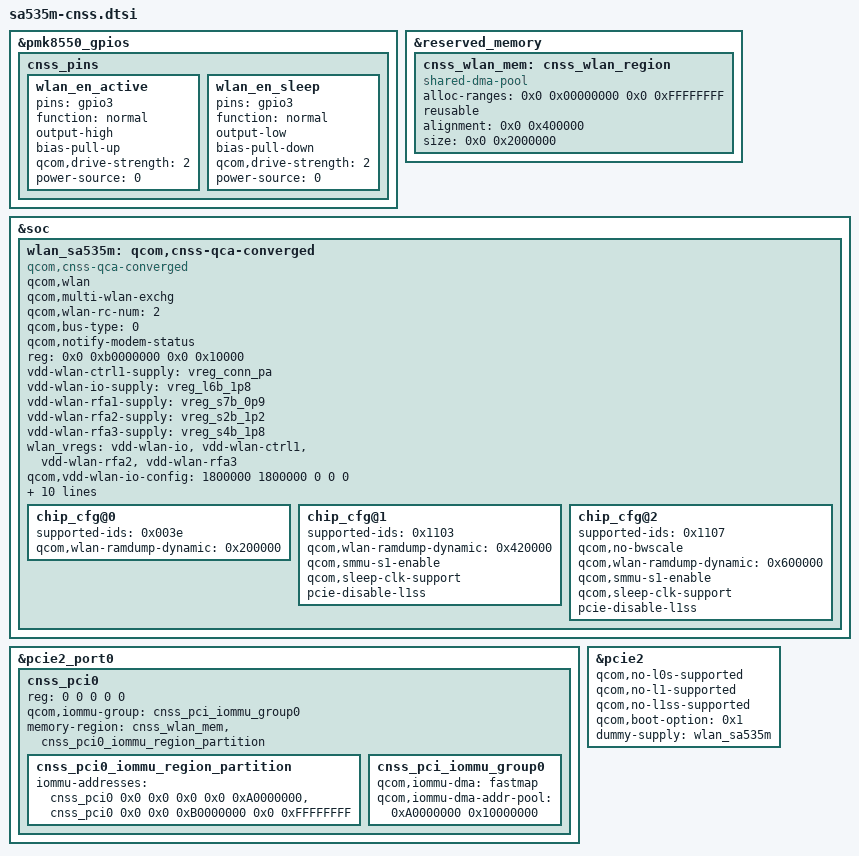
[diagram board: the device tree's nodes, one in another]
// SPDX-License-Identifier: BSD-3-Clause
/*
 * Copyright (c) Qualcomm Technologies, Inc. and/or its subsidiaries.
 */

#include <dt-bindings/interconnect/qcom,echo.h>
#include <dt-bindings/clock/qcom,rpmh.h>
#include <dt-bindings/iio/qcom,spmi-adc5-gen3-pmk8550.h>
#include <dt-bindings/pinctrl/qcom,pmic-gpio.h>
&pmk8550_gpios {
	cnss_pins {
		wlan_en_active: wlan_en_active {
			pins = "gpio3";
			function = "normal";
			output-high;
			bias-pull-up;
			qcom,drive-strength = <2>;
			power-source = <0>;
		};

		wlan_en_sleep: wlan_en_sleep {
			pins = "gpio3";
			function = "normal";
			output-low;
			bias-pull-down;
			qcom,drive-strength = <2>;
			power-source = <0>;
		};
	};
};

&reserved_memory {
	cnss_wlan_mem: cnss_wlan_region {
		compatible = "shared-dma-pool";
		alloc-ranges = <0x0 0x00000000 0x0 0xFFFFFFFF>;
		reusable;
		alignment = <0x0 0x400000>;
		size = <0x0 0x2000000>;
	};
};

&soc {
	wlan_sa535m: qcom,cnss-qca-converged {
		compatible = "qcom,cnss-qca-converged";
		qcom,wlan;
		qcom,multi-wlan-exchg;
		qcom,wlan-rc-num = <2>;
		qcom,bus-type=<0>;
		qcom,notify-modem-status;
		reg = <0x0 0xb0000000 0x0 0x10000>;
		reg-names = "smmu_iova_ipa";

		vdd-wlan-ctrl1-supply = <&vreg_conn_pa>;
		vdd-wlan-io-supply = <&vreg_l6b_1p8>;
		vdd-wlan-rfa1-supply = <&vreg_s7b_0p9>;
		vdd-wlan-rfa2-supply = <&vreg_s2b_1p2>;
		vdd-wlan-rfa3-supply = <&vreg_s4b_1p8>;
		wlan_vregs = "vdd-wlan-io", "vdd-wlan-ctrl1",
				"vdd-wlan-rfa2", "vdd-wlan-rfa3";
		qcom,vdd-wlan-io-config = <1800000 1800000 0 0 0>;
		qcom,vdd-wlan-ctrl1-config = <0 0 0 0 0>;
		qcom,vdd-wlan-rfa1-config = <1000000 1000000 0 0 0>;
		qcom,vdd-wlan-rfa2-config = <1300000 1300000 0 0 0>;
		qcom,vdd-wlan-rfa3-config = <1904000 1904000 450000 0 0>;
		wlan-en-gpio = <&pmk8550_gpios 3 0>;
		pinctrl-names = "wlan_en_active", "wlan_en_sleep";
		pinctrl-0 = <&wlan_en_active>;
		pinctrl-1 = <&wlan_en_sleep>;

		chip_cfg@0 {
			supported-ids = <0x003e>;
			qcom,wlan-ramdump-dynamic = <0x200000>;
		};

		chip_cfg@1 {
			supported-ids = <0x1103>;
			qcom,wlan-ramdump-dynamic = <0x420000>;
			qcom,smmu-s1-enable;
			qcom,sleep-clk-support;
			pcie-disable-l1ss;
		};

		chip_cfg@2 {
			supported-ids = <0x1107>;
			qcom,no-bwscale;
			qcom,wlan-ramdump-dynamic = <0x600000>;
			qcom,smmu-s1-enable;
			qcom,sleep-clk-support;
			pcie-disable-l1ss;
		};
	};
};

&pcie2_port0 {
	cnss_pci0: cnss_pci0 {
		reg = <0 0 0 0 0>;
		qcom,iommu-group = <&cnss_pci_iommu_group0>;
		memory-region = <&cnss_wlan_mem &cnss_pci0_iommu_region_partition>;

		cnss_pci0_iommu_region_partition: cnss_pci0_iommu_region_partition {
			iommu-addresses = <&cnss_pci0 0x0 0x0 0x0 0x0 0xA0000000>,
					  <&cnss_pci0 0x0 0x0 0xB0000000 0x0 0xFFFFFFFF>;
		};

		/* Used by cnss2 only for compatibility */
		cnss_pci_iommu_group0: cnss_pci_iommu_group0 {
			qcom,iommu-dma = "fastmap";
			qcom,iommu-dma-addr-pool = <0xA0000000 0x10000000>;
		};
	};
};

&pcie2 {
	qcom,no-l0s-supported;
	qcom,no-l1-supported;
	qcom,no-l1ss-supported;
	qcom,boot-option = <0x1>;
	status = "ok";

	/* Ensure that PCIe RC driver probe is deferred until CNSS is probed */
	dummy-supply = <&wlan_sa535m>;
};

